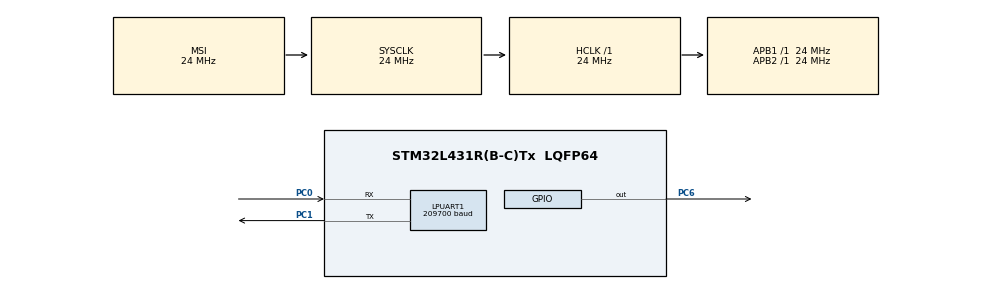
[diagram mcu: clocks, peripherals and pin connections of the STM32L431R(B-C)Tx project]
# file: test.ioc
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LPUART1.BaudRate=209700
Mcu.Family=STM32L4
Mcu.Name=STM32L431R(B-C)Tx
Mcu.Package=LQFP64
NVIC.LPUART1_IRQn=true\:0\:0\:false\:false\:true\:true\:true\:true
NVIC.PVD_PVM_IRQn=true\:0\:0\:false\:false\:true\:true\:true\:true
NVIC.PriorityGroup=NVIC_PRIORITYGROUP_4
NVIC.RTC_Alarm_IRQn=true\:0\:0\:false\:false\:true\:true\:true\:true
PA0.Mode=SYS_WakeUp0
PA0.Signal=SYS_WKUP1
PA13\ (JTMS-SWDIO).Mode=Serial_Wire
PA13\ (JTMS-SWDIO).Signal=SYS_JTMS-SWDIO
PA14\ (JTCK-SWCLK).Mode=Serial_Wire
PA14\ (JTCK-SWCLK).Signal=SYS_JTCK-SWCLK
PC0.Mode=Asynchronous
PC0.Signal=LPUART1_RX
PC1.Mode=Asynchronous
PC1.Signal=LPUART1_TX
PC14-OSC32_IN\ (PC14).Mode=LSE-External-Oscillator
PC14-OSC32_IN\ (PC14).Signal=RCC_OSC32_IN
PC15-OSC32_OUT\ (PC15).Mode=LSE-External-Oscillator
PC15-OSC32_OUT\ (PC15).Signal=RCC_OSC32_OUT
PC6.Signal=GPIO_Output
PH0-OSC_IN\ (PH0).Mode=HSE-External-Oscillator
PH0-OSC_IN\ (PH0).Signal=RCC_OSC_IN
PH1-OSC_OUT\ (PH1).Mode=HSE-External-Oscillator
PH1-OSC_OUT\ (PH1).Signal=RCC_OSC_OUT
ProjectManager.HeapSize=0x200
ProjectManager.StackSize=0x400
ProjectManager.TargetToolchain=MDK-ARM V5.32
RCC.ADCFreq_Value=96000000
RCC.AHBFreq_Value=24000000
RCC.APB1Freq_Value=24000000
RCC.APB1TimFreq_Value=24000000
RCC.APB2Freq_Value=24000000
RCC.APB2TimFreq_Value=24000000
RCC.CortexFreq_Value=24000000
RCC.HCLKFreq_Value=24000000
RCC.HSE_VALUE=8000000
RCC.HSI48_VALUE=48000000
RCC.HSI_VALUE=16000000
RCC.MSIClockRange=RCC_MSIRANGE_9
RCC.MSI_VALUE=24000000
RCC.PLLN=12
RCC.PLLR=RCC_PLLR_DIV4
RCC.RTCClockSelection=RCC_RTCCLKSOURCE_LSE
RCC.SYSCLKFreq_VALUE=24000000
RCC.VCOOutputFreq_Value=288000000
RTC.Alarm-Alarm\ A=RTC_ALARM_A
VP_RTC_VS_RTC_Activate.Mode=RTC_Enabled
VP_RTC_VS_RTC_Alarm_A_Intern.Mode=Alarm A
VP_RTC_VS_RTC_Calendar.Mode=RTC_Calendar
board=custom

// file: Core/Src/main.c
/* USER CODE BEGIN Header */
/**
  ******************************************************************************
  * @file           : main.c
  * @brief          : Main program body
  ******************************************************************************
  * @attention
  *
  * Copyright (c) 2026 STMicroelectronics.
  * All rights reserved.
  *
  * This software is licensed under terms that can be found in the LICENSE file
  * in the root directory of this software component.
  * If no LICENSE file comes with this software, it is provided AS-IS.
  *
  ******************************************************************************
  */
/* USER CODE END Header */
#include "main.h"
#include "usart.h"
#include "rtc.h"
#include "gpio.h"

/* USER CODE BEGIN Includes */
#include "stop.h"

/* USER CODE END Includes */

void SystemClock_Config(void);

/* USER CODE BEGIN 0 */
uint8_t lpuart_buf;
//void Enter_Sleep(void)
//{
//	//进入睡眠前挂起的滴答时钟
//	HAL_SuspendTick();
//	//进入睡眠模式
//	HAL_PWR_EnterSLEEPMode(PWR_MAINREGULATOR_ON, PWR_SLEEPENTRY_WFI);
//	//唤醒后恢复
//	HAL_ResumeTick();
//}

//void Enter_Stop2(void){
//	HAL_SuspendTick();
//	HAL_PWREx_EnterSTOP2Mode(PWR_STOPENTRY_WFI);
//	HAL_ResumeTick();
////	SystemClock_Config();
//
//
//}

/* USER CODE END 0 */

int main(void)
{

  /* MCU Configuration--------------------------------------------------------*/

  /* Reset of all peripherals, Initializes the Flash interface and the Systick. */
  HAL_Init();

  /* Configure the system clock */
  SystemClock_Config();

  /* Initialize all configured peripherals */
  MX_GPIO_Init();
  MX_LPUART1_UART_Init();
  MX_RTC_Init();
  /* USER CODE BEGIN 2 */
	HAL_Delay(5000);
	HAL_UART_Receive_IT(&hlpuart1, &lpuart_buf, 1);
  /* USER CODE END 2 */

  /* Infinite loop */
  while (1)
  {

    /* USER CODE BEGIN 3 */

//		RTC_Set_Alarm(3);
//		Enter_Sleep();
		// 唤醒后 ↓
//		HAL_GPIO_TogglePin(GPIOC, GPIO_PIN_6); // LED 翻转

		// 2. Stop2 1800秒
		//RTC_Set_Alarm(30 * 60);
		RTC_Set_Alarm(3);
		Enter_Stop2();
		// 唤醒后 ↓
		HAL_GPIO_TogglePin(GPIOC, GPIO_PIN_6); // LED 翻转

  }
  /* USER CODE END 3 */
}

void SystemClock_Config(void)
{
  RCC_OscInitTypeDef RCC_OscInitStruct = {0};
  RCC_ClkInitTypeDef RCC_ClkInitStruct = {0};

  /** Configure the main internal regulator output voltage
  */
  if (HAL_PWREx_ControlVoltageScaling(PWR_REGULATOR_VOLTAGE_SCALE1) != HAL_OK)
  {
    Error_Handler();
  }

  /** Configure LSE Drive Capability
  */
  HAL_PWR_EnableBkUpAccess();
  __HAL_RCC_LSEDRIVE_CONFIG(RCC_LSEDRIVE_LOW);

  /** Initializes the RCC Oscillators according to the specified parameters
  * in the RCC_OscInitTypeDef structure.
  */
  RCC_OscInitStruct.OscillatorType = RCC_OSCILLATORTYPE_LSE|RCC_OSCILLATORTYPE_MSI;
  RCC_OscInitStruct.LSEState = RCC_LSE_ON;
  RCC_OscInitStruct.MSIState = RCC_MSI_ON;
  RCC_OscInitStruct.MSICalibrationValue = 0;
  RCC_OscInitStruct.MSIClockRange = RCC_MSIRANGE_9;
  RCC_OscInitStruct.PLL.PLLState = RCC_PLL_NONE;
  if (HAL_RCC_OscConfig(&RCC_OscInitStruct) != HAL_OK)
  {
    Error_Handler();
  }

  /** Initializes the CPU, AHB and APB buses clocks
  */
  RCC_ClkInitStruct.ClockType = RCC_CLOCKTYPE_HCLK|RCC_CLOCKTYPE_SYSCLK
                              |RCC_CLOCKTYPE_PCLK1|RCC_CLOCKTYPE_PCLK2;
  RCC_ClkInitStruct.SYSCLKSource = RCC_SYSCLKSOURCE_MSI;
  RCC_ClkInitStruct.AHBCLKDivider = RCC_SYSCLK_DIV1;
  RCC_ClkInitStruct.APB1CLKDivider = RCC_HCLK_DIV1;
  RCC_ClkInitStruct.APB2CLKDivider = RCC_HCLK_DIV1;

  if (HAL_RCC_ClockConfig(&RCC_ClkInitStruct, FLASH_LATENCY_1) != HAL_OK)
  {
    Error_Handler();
  }

  /** Enable MSI Auto calibration
  */
  HAL_RCCEx_EnableMSIPLLMode();
}

/* USER CODE BEGIN 4 */
void HAL_GPIO_EXTI_Callback(uint16_t GPIO_Pin){

}

void HAL_RTC_AlarmAEventCallback(RTC_HandleTypeDef *hrtc){

}

void HAL_UART_RxCpltCallback(UART_HandleTypeDef *huart){
	if(huart->Instance == LPUART1)
  {
    // �յ����ݣ�lpuart_buf
    // ���¿�������
    HAL_UART_Receive_IT(&hlpuart1, &lpuart_buf, 1);
  }
}

/* USER CODE END 4 */

void Error_Handler(void)
{
  __disable_irq();
  while (1)
  {
  }
}
